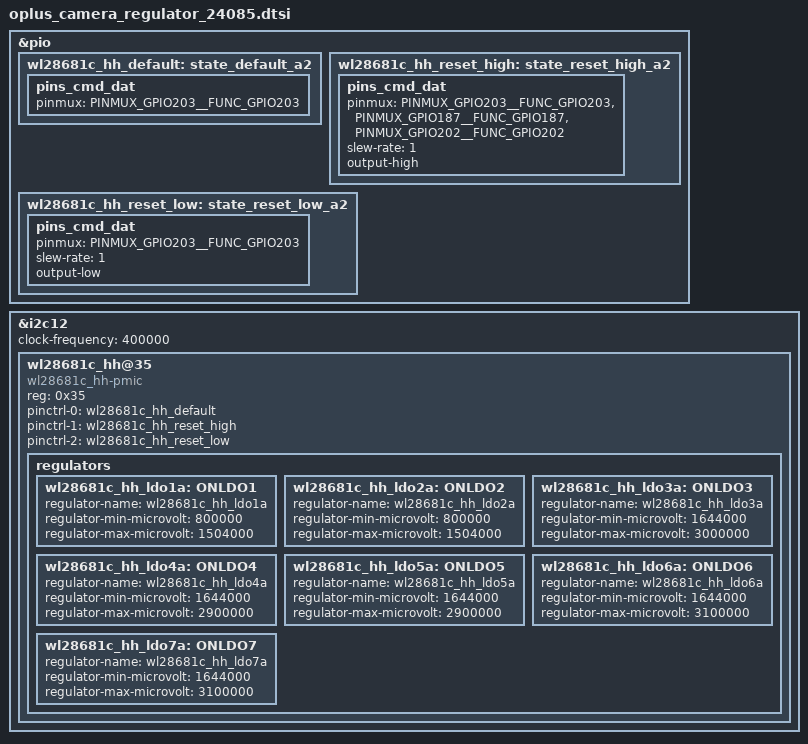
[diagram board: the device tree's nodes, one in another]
// SPDX-License-Identifier: GPL-2.0
/*
 * Copyright (C) 2021 MediaTek Inc.
 */

&pio {
	wl28681c_hh_default: state_default_a2 {
		pins_cmd_dat {
			pinmux = <PINMUX_GPIO203__FUNC_GPIO203>;
		};
	};
	// GPIO187/GPIO202 pull up to enable CAMERA_DCDC_1P3/CAMERA_DCDC_3P2
	wl28681c_hh_reset_high: state_reset_high_a2 {
		pins_cmd_dat {
			pinmux = <PINMUX_GPIO203__FUNC_GPIO203>,
			<PINMUX_GPIO187__FUNC_GPIO187>,
			<PINMUX_GPIO202__FUNC_GPIO202>;
			slew-rate = <1>;
			output-high;
		};
	};
	wl28681c_hh_reset_low: state_reset_low_a2 {
		pins_cmd_dat {
			pinmux = <PINMUX_GPIO203__FUNC_GPIO203>;
			slew-rate = <1>;
			output-low;
		};
	};
};

&i2c12 {
	clock-frequency = <400000>;
	wl28681c_hh@35 {
		compatible = "wl28681c_hh-pmic";
		reg = <0x35>;
		pinctrl-names = "default", "reset_high", "reset_low";
		pinctrl-0 = <&wl28681c_hh_default>;
		pinctrl-1 = <&wl28681c_hh_reset_high>;
		pinctrl-2 = <&wl28681c_hh_reset_low>;
		regulators {
			wl28681c_hh_ldo1a:ONLDO1 {
				regulator-name = "wl28681c_hh_ldo1a";
				regulator-min-microvolt = <800000>;
				regulator-max-microvolt = <1504000>;
			};
			wl28681c_hh_ldo2a:ONLDO2 {
				regulator-name = "wl28681c_hh_ldo2a";
				regulator-min-microvolt = <800000>;
				regulator-max-microvolt = <1504000>;
			};
			wl28681c_hh_ldo3a:ONLDO3 {
				regulator-name = "wl28681c_hh_ldo3a";
				regulator-min-microvolt = <1644000>;
				regulator-max-microvolt = <3000000>;
			};
			wl28681c_hh_ldo4a:ONLDO4 {
				regulator-name = "wl28681c_hh_ldo4a";
				regulator-min-microvolt = <1644000>;
				regulator-max-microvolt = <2900000>;
			};
			//
			wl28681c_hh_ldo5a:ONLDO5 {
				regulator-name = "wl28681c_hh_ldo5a";
				regulator-min-microvolt = <1644000>;
				regulator-max-microvolt = <2900000>;
			};
			wl28681c_hh_ldo6a:ONLDO6 {
				regulator-name = "wl28681c_hh_ldo6a";
				regulator-min-microvolt = <1644000>;
				regulator-max-microvolt = <3100000>;
			};
			wl28681c_hh_ldo7a:ONLDO7 {
				regulator-name = "wl28681c_hh_ldo7a";
				regulator-min-microvolt = <1644000>;
				regulator-max-microvolt = <3100000>;
			};
		};
	};
};



